# A31G33x register map
Vendor: VENDOR ABOV Semiconductor Co., Ltd.; Series: A31G33x; File version: 1.0
CPU: CM0+ r0p1, little endian, no MPU, no FPU, VTOR, 2 interrupt priority bits
Registers are 32-bit, read-only, no defined reset value unless marked. A register's access mark holds for its fields unless they carry their own. Offsets are from the block's base; [hi:lo] are bit positions.

## SCUCG — System Control Unit: Clock Generation
Base 0x40001800
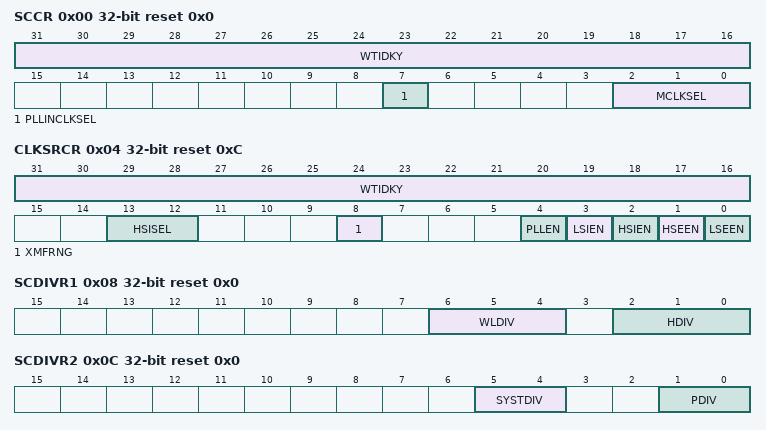
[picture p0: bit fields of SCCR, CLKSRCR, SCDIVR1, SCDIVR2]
0x00 SCCR rw reset 0x0 — System Clock Control Register
  [31:16] WTIDKY wo — Write Identification Key (0x570a)
    0x570A=Value (Key Value (0x570a))
  [7] PLLINCLKSEL — PLL Input Clock Source Selection
    0=HSI (The HSI clock selected by CLKSRCR.HSISEL[1:0] is used as PLL input clock); 1=HSE (A HSE clock is used as PLL input clock)
  [2:0] MCLKSEL — Main Clock Selection, MCLK
    0=HSI (High speed Internal RC oscillator (32MHz), HSI); 1=HSE (External main oscillator (2 - 48MHz), HSE); 2=LSE (External sub oscillator (32.768kHz), LSE); 3=LSI (Low speed Internal RC oscillator (40kHz), LSI); 4=PLL (PLL output clock)
0x04 CLKSRCR rw reset 0xC — Clock Source Control Register
  [31:16] WTIDKY wo — Write Identification Key (0xa507)
    0xA507=Value (Key Value (0xa507))
  [13:12] HSISEL — HSI Frequency Selection
    0=HSI1 (32MHz HSI); 1=HSI2 (16MHz HSI); 2=HSI4 (8MHz HSI); 3=HSI8 (4MHz HSI)
  [8] XMFRNG — Main Oscillator Type and Frequency Range Selection
    0=x-tal for HSE, 2 to 16MHz; 1=Clock (External clock for HSE, 2MHz to 48MHz)
  [4] PLLEN — PLL Enable
    0=Disable PLL; 1=Enable PLL
  [3] LSIEN — LSI Enable
    0=Disable LSI; 1=Enable LSI
  [2] HSIEN — HSI Enable
    0=Disable HSI; 1=Enable HSI
  [1] HSEEN — HSE Enable
    0=Disable HSE; 1=Enable HSE
  [0] LSEEN — LSE Enable
    0=Disable LSE; 1=Enable LSE
0x08 SCDIVR1 rw reset 0x0 — System Clock Divide Register 1
  [6:4] WLDIV — Clock Divide for RTCC, Divider 2
    0=MCLK64; 1=MCLK128; 2=MCLK256; 3=MCLK512; 4=MCLK1024
  [2:0] HDIV — Clock Divide for HCLK, Divider 0
    0=MCLK16; 1=MCLK8; 2=MCLK4; 3=MCLK2; 4=MCLK1
0x0C SCDIVR2 rw reset 0x0 — System Clock Divide Register 2
  [5:4] SYSTDIV — Clock Divide for SysTick Timer, Divider 3
    0=HCLK1; 1=HCLK2; 2=HCLK4; 3=HCLK8
  [1:0] PDIV — Clock Divide for PCLK, Divider 1
    0=HCLK1; 1=HCLK2; 2=HCLK4; 3=HCLK8
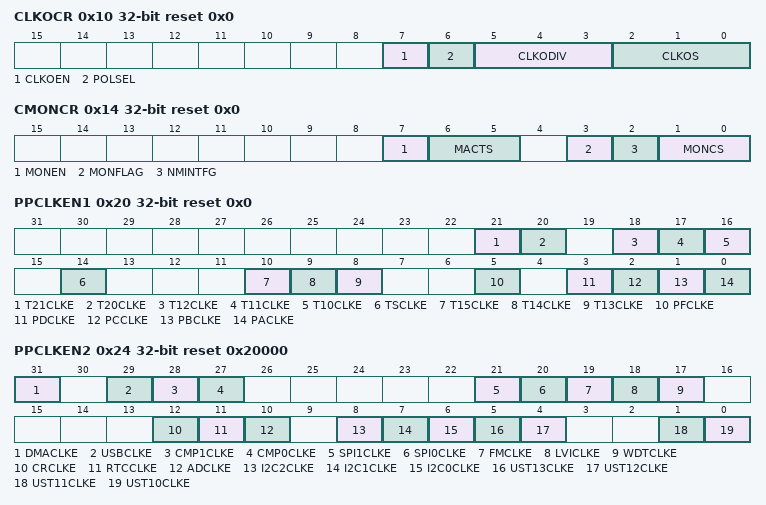
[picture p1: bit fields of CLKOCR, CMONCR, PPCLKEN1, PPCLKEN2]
0x10 CLKOCR rw reset 0x0 — Clock Output Control Register
  [7] CLKOEN — Clock Output Enable
    0=Disable clock output; 1=Enable clock output
  [6] POLSEL — Clock Output Polarity Selection when disable
    0=Low (Low level during disable); 1=High level during disable
  [5:3] CLKODIV — Output Clock Divide, Divider 4
    0=SelectedClock1; 1=SelectedClock2; 2=SelectedClock4; 3=SelectedClock8; 4=SelectedClock16; 5=SelectedClock32; 6=SelectedClock64; 7=SelectedClock128
  [2:0] CLKOS — Clock Output Selection
    0=MCLK (Select MCLK.); 1=LSI (Select LSI.); 2=HSI (Select HSI.); 3=HCLK (Select HCLK.); 4=PCLK (Select PCLK.)
0x14 CMONCR rw reset 0x0 — Clock Monitoring Control Register
  [7] MONEN — Clock Monitoring Enable
    0=Disable clock monitoring; 1=Enable clock monitoring
  [6:5] MACTS — Clock Monitoring Action Selection
    0=FlagChk (No action by clock monitoring, but flags will be set/cleared on condition); 1=RstGen (Reset generation by clock monitoring); 2=SysClkChg (The system clock will be changed to the LSI regardless of MCLKSEL[1:0] bits of system clock control register (SCU_SCCR) only when the MCLK is selected for monitoring)
  [3] MONFLAG — Clock Monitoring Result Flag
    0=NotReady (The clock to be monitored is not ready); 1=Ready (The clock to be monitored is ready)
  [2] NMINTFG — Clock Monitoring Interrupt Flag
    0=No request occurred; 1=Request occurred
  [1:0] MONCS — Monitored Clock Selection
    0=MCLK (Select MCLK.); 1=HSI (Select HSI.); 2=HSE (Select HSE.); 3=LSE (Select LSE.)
0x20 PPCLKEN1 rw reset 0x0 — Peripheral Clock Enable Register 1
  [all] fields
    0=Disable clock; 1=Enable clock
  [21] T21CLKE — TIMER21 Clock Enable
  [20] T20CLKE — TIMER20 Clock Enable
  [18] T12CLKE — TIMER12 Clock Enable
  [17] T11CLKE — TIMER11 Clock Enable
  [16] T10CLKE — TIMER10 Clock Enable
  [14] TSCLKE — TS Clock Enable
  [10] T15CLKE — TIMER15 Clock Enable
  [9] T14CLKE — TIMER14 Clock Enable
  [8] T13CLKE — TIMER13 Clock Enable
  [5] PFCLKE — Port F Clock Enable
  [3] PDCLKE — Port D Clock Enable
  [2] PCCLKE — Port C Clock Enable
  [1] PBCLKE — Port B Clock Enable
  [0] PACLKE — Port A Clock Enable
0x24 PPCLKEN2 rw reset 0x20000 — Peripheral Clock Enable Register 2
  [all] fields
    0=Disable clock; 1=Enable clock
  [31] DMACLKE — DMAC (DMA Controller) Clock Enable
  [29] USBCLKE — USB Clock Enable
  [28] CMP1CLKE — CMP1 (Comparator) Clock Enable
  [27] CMP0CLKE — CMP0 (Comparator) Clock Enable
  [21] SPI1CLKE — SPI1 Clock Enable
  [20] SPI0CLKE — SPI0 Clock Enable
  [19] FMCLKE — FMC (Flash Memory Controller) Clock Enable
  [18] LVICLKE — LVI (Low Voltage Indicator) Clock Enable
  [17] WDTCLKE — WDT (Watch-Dog Timer) Clock Enable
  [12] CRCLKE — CRC (Cyclic Redundancy Check) Clock Enable
  [11] RTCCLKE — RTCC (Real Time Clock/Calendar) Clock Enable
  [10] ADCLKE — ADC (Analog to Digital Converter) Clock Enable
  [8] I2C2CLKE — I2C2 (Inter-IC) Clock Enable
  [7] I2C1CLKE — I2C1 (Inter-IC) Clock Enable
  [6] I2C0CLKE — I2C0 (Inter-IC) Clock Enable
  [5] UST13CLKE — USART13 Clock Enable
  [4] UST12CLKE — USART12 Clock Enable
  [1] UST11CLKE — USART11 Clock Enable
  [0] UST10CLKE — USART10 Clock Enable
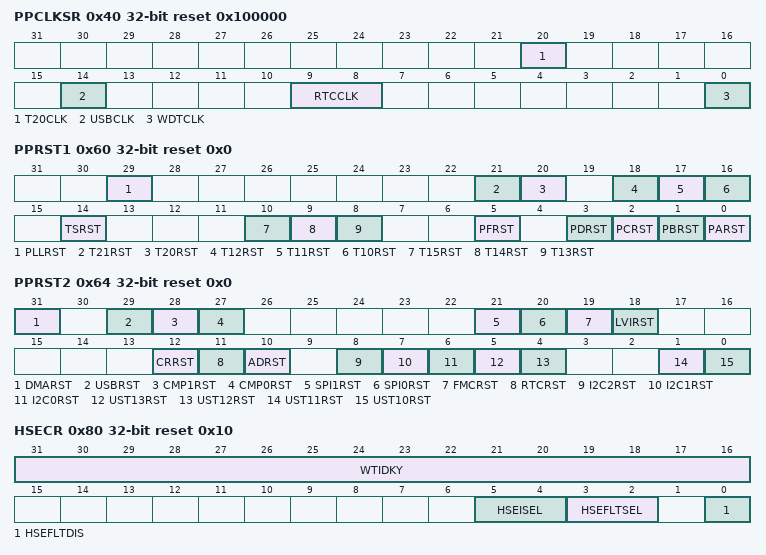
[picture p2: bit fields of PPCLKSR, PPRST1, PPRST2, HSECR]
0x40 PPCLKSR rw reset 0x100000 — Peripheral Clock Selection Register
  [20] T20CLK — TIMER20 Clock Selection
    0=LSE (LSE clock); 1=PCLK (PCLK clock)
  [14] USBCLK — USB Clock Selection
    0=HSE (HSE clock); 1=PLL (PLL out)
  [9:8] RTCCLK — RTCC (Real Time Clock/Calendar) Clock Selection
    0=Low level (RTC stuck); 1=LSE (LSE clock); 2=LSI (LSI clock)
  [0] WDTCLK — WDT (Watch-Dog Timer) Clock Selection
    0=LSI (LSI clock); 1=PCLK (PCLK clock)
0x60 PPRST1 rw reset 0x0 — Peripheral Reset Register 1
  [29] PLLRST — PLL Reset
  [21] T21RST — TIMER21 Reset
  [20] T20RST — TIMER20 Reset
  [18] T12RST — TIMER12 Reset
  [17] T11RST — TIMER11 Reset
  [16] T10RST — TIMER10 Reset
  [14] TSRST — TS Reset
  [10] T15RST — TIMER15 Reset
  [9] T14RST — TIMER14 Reset
  [8] T13RST — TIMER13 Reset
  [5] PFRST — Port F Reset
  [3] PDRST — Port D Reset
  [2] PCRST — Port C Reset
  [1] PBRST — Port B Reset
  [0] PARST — Port A Reset
0x64 PPRST2 rw reset 0x0 — Peripheral Reset Register 2
  [31] DMARST — DMAC (DMA Controller) Reset
  [29] USBRST — USB Reset
  [28] CMP1RST — CMP1 (Comparator) Reset
  [27] CMP0RST — CMP0 (Comparator) Reset
  [21] SPI1RST — SPI1 Reset
  [20] SPI0RST — SPI0 Reset
  [19] FMCRST — FMC (Flash Memory Controller) Reset
  [18] LVIRST — LVI (Low Voltage Indicator) Reset
  [12] CRRST — CRC (Cyclic Redundancy Check) Reset
  [11] RTCRST — RTCC (Real Time Clock/Calendar) Reset
  [10] ADRST — ADC (Analog to Digital Converter) Reset
  [8] I2C2RST — I2C2 (Inter-IC) Reset
  [7] I2C1RST — I2C1 (Inter-IC) Reset
  [6] I2C0RST — I2C0 (Inter-IC) Reset
  [5] UST13RST — USART13 Reset
  [4] UST12RST — USART12 Reset
  [1] UST11RST — USART11 Reset
  [0] UST10RST — USART10 Reset
0x80 HSECR rw reset 0x10 — External Main Oscillator Control Register
  [31:16] WTIDKY wo — Write Identification Key (0x9b37)
    0x9B37=Value (Key Value (0x9b37))
  [5:4] HSEISEL — External Main Oscillator Current Selection
    0=High current for HSE; 1=Mid-high current for HSE; 2=Mid-low current for HSE; 3=Low (Low current for HSE)
  [3:2] HSEFLTSEL — External Main Oscillator Filter Selection
    0=12MHz_16MHz (12MHz GT HSE LE 16MHz); 1=8MHz_12MHz (8MHz GT HSE LE 12MHz); 2=4MHz_8MHz (4MHz GT HSE LE 8MHz); 3=2MHz_4MHz (2MHz GT HSE LE 4MHz)
  [0] HSEFLTDIS — External Main Oscillator Filter Enable
    0=Enable noise filter for HSE; 1=Disable noise filter for HSE
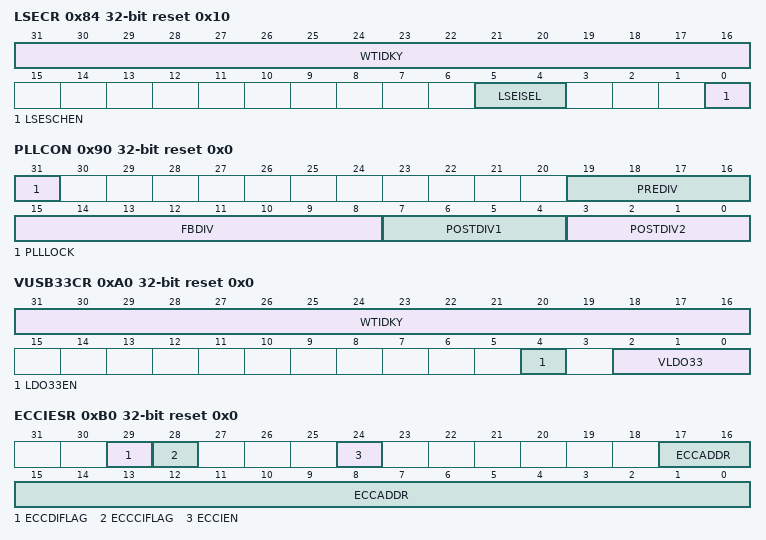
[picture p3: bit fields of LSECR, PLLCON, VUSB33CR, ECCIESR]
0x84 LSECR rw reset 0x10 — External Sub Oscillator Control Register
  [31:16] WTIDKY wo — Write Identification Key (0x40c3)
    0x40C3=Value (Key Value (0x40c3))
  [5:4] LSEISEL — External Sub Oscillator Current Selection
    0=High current for LSE; 1=Mid-high current for LSE; 2=Mid-low current for LSE; 3=Low (Low current for LSE)
  [0] LSESCHEN — External Sub Oscillator Schmitt Trigger Enable
    0=Disable schmitt trigger for LSE; 1=Enable schmitt trigger for LSE
0x90 PLLCON rw reset 0x0 — PLL Clock Control Register
  [31] PLLLOCK ro — PLL Lock Status
    0=NotLocked (PLL is not locked); 1=Locked (PLL is locked)
  [19:16] PREDIV — PLL Input Clock Pre-divider bits (R). The range is 0 to 15.
  [15:8] FBDIV — PLL Feedback divider bits (FB). The range is 0 to 255.
  [7:4] POSTDIV1 — PLL Post-1 divider bits (N1). The range is 0 to 15.
  [3:0] POSTDIV2 — PLL Post-2 divider bits (N2). The range is 0 to 15.
0xA0 VUSB33CR rw reset 0x0 — VUSB33 Control Register
  [31:16] WTIDKY wo — Write Identification Key (0xa369)
    0xA369=Value (Key Value (0xa369))
  [4] LDO33EN — LDO33 Enable
    0=Disable LDO33; 1=Enable LDO33
  [2:0] VLDO33 — VUSB33 Pin Voltage Control
    1=LDO33 (The VUSB33 pin is the output voltage of internal LDO.); 2=VDD (The VUSB33 pin is the same voltage as VDD.); 4=External (An external 3.3V should be connected to the VUSB33 pin for USB operation.); 0=Floating (The VUSB33 pin is floating state.)
0xB0 ECCIESR rw reset 0x0 — Flash ECC Interrupt Enable and Status Register
  [29] ECCDIFLAG — ECC Detection Interrupt flag.
    0=No request occurred; 1=Request occurred
  [28] ECCCIFLAG — ECC Correction Interrupt flag.
    0=No request occurred; 1=Request occurred
  [24] ECCIEN — ECC Correction Interrupt Enable
    0=Disable ECC correction interrupt; 1=Enable ECC correction interrupt
  [17:0] ECCADDR ro — Flash ECC Error or Correction Address
